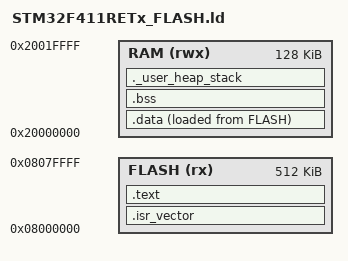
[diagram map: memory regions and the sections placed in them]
/* Linker script for STM32F411RE - 512K Flash, 128K SRAM */
ENTRY(Reset_Handler)

MEMORY
{
  FLASH (rx)  : ORIGIN = 0x08000000, LENGTH = 512K
  RAM   (rwx) : ORIGIN = 0x20000000, LENGTH = 128K
}

_estack = ORIGIN(RAM) + LENGTH(RAM);

SECTIONS
{
  .isr_vector :
  {
    . = ALIGN(4);
    KEEP(*(.isr_vector))
    . = ALIGN(4);
  } >FLASH

  .text :
  {
    . = ALIGN(4);
    *(.text)
    *(.text*)
    *(.rodata)
    *(.rodata*)
    KEEP(*(.init))
    KEEP(*(.fini))
    . = ALIGN(4);
    _etext = .;
  } >FLASH

  .data :
  {
    . = ALIGN(4);
    _sdata = .;
    *(.data)
    *(.data*)
    . = ALIGN(4);
    _edata = .;
  } >RAM AT>FLASH

  .bss :
  {
    . = ALIGN(4);
    _sbss = .;
    *(.bss)
    *(.bss*)
    *(COMMON)
    . = ALIGN(4);
    _ebss = .;
  } >RAM

  ._user_heap_stack :
  {
    . = ALIGN(8);
    PROVIDE(end = .);
    . = . + 0x400;
    . = . + 0x800;
    . = ALIGN(8);
  } >RAM
}
